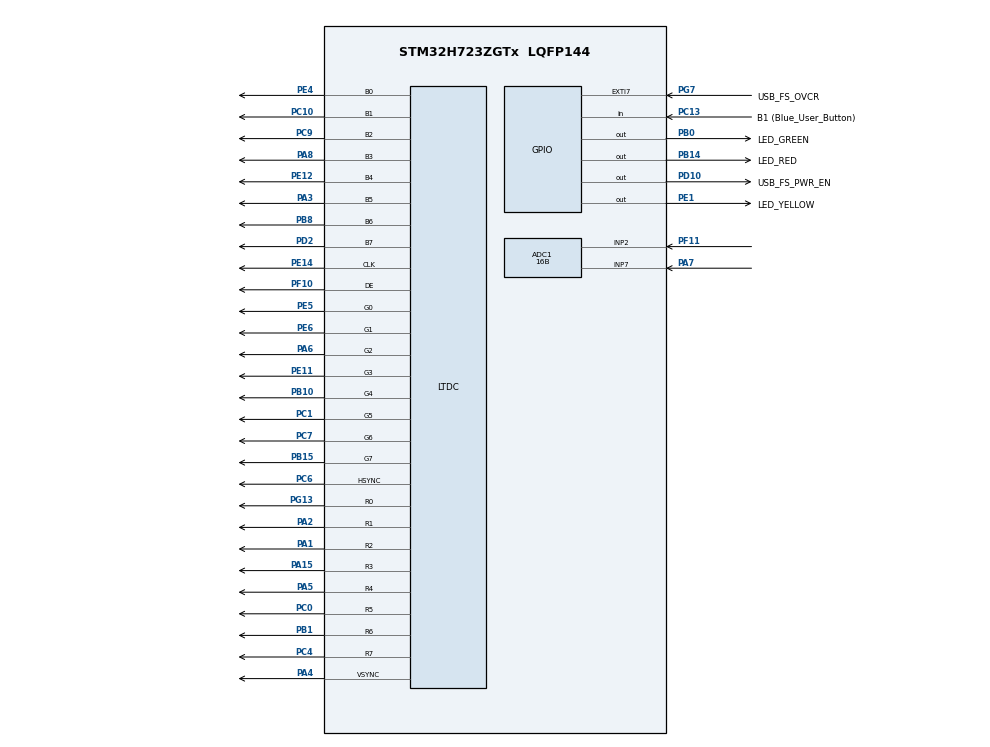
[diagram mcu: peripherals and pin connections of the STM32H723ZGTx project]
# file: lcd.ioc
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ADC1.Channel-1\#ChannelRegularConversion=ADC_CHANNEL_2
ADC1.Channel-2\#ChannelRegularConversion=ADC_CHANNEL_7
ADC1.ContinuousConvMode=DISABLE
ADC1.ConversionDataManagement=ADC_CONVERSIONDATA_DMA_CIRCULAR
ADC1.EOCSelection=ADC_EOC_SEQ_CONV
ADC1.NbrOfConversion=2
ADC1.NbrOfConversionFlag=1
ADC1.OffsetNumber-1\#ChannelRegularConversion=ADC_OFFSET_NONE
ADC1.OffsetNumber-2\#ChannelRegularConversion=ADC_OFFSET_NONE
ADC1.OffsetSignedSaturation-1\#ChannelRegularConversion=DISABLE
ADC1.OffsetSignedSaturation-2\#ChannelRegularConversion=DISABLE
ADC1.Overrun=ADC_OVR_DATA_PRESERVED
ADC1.Rank-1\#ChannelRegularConversion=1
ADC1.Rank-2\#ChannelRegularConversion=2
ADC1.Resolution=ADC_RESOLUTION_16B
ADC1.SamplingTime-1\#ChannelRegularConversion=ADC_SAMPLETIME_1CYCLE_5
ADC1.SamplingTime-2\#ChannelRegularConversion=ADC_SAMPLETIME_1CYCLE_5
ADC1.master=1
Dma.ADC1.0.Direction=DMA_PERIPH_TO_MEMORY
Dma.ADC1.0.EventEnable=DISABLE
Dma.ADC1.0.FIFOMode=DMA_FIFOMODE_DISABLE
Dma.ADC1.0.Instance=DMA1_Stream0
Dma.ADC1.0.MemDataAlignment=DMA_MDATAALIGN_HALFWORD
Dma.ADC1.0.MemInc=DMA_MINC_ENABLE
Dma.ADC1.0.Mode=DMA_CIRCULAR
Dma.ADC1.0.PeriphDataAlignment=DMA_PDATAALIGN_HALFWORD
Dma.ADC1.0.PeriphInc=DMA_PINC_DISABLE
Dma.ADC1.0.Polarity=HAL_DMAMUX_REQ_GEN_RISING
Dma.ADC1.0.Priority=DMA_PRIORITY_LOW
Dma.ADC1.0.RequestNumber=1
Dma.ADC1.0.SignalID=NONE
Dma.ADC1.0.SyncEnable=DISABLE
Dma.ADC1.0.SyncPolarity=HAL_DMAMUX_SYNC_NO_EVENT
Dma.ADC1.0.SyncRequestNumber=1
Dma.ADC1.0.SyncSignalID=NONE
Dma.Request0=ADC1
LTDC.ActiveH=480
LTDC.ActiveW=800
LTDC.Alpha_L0=255
LTDC.DEPolarity=LTDC_DEPOLARITY_AH
LTDC.HBP=8
LTDC.HFP=8
LTDC.HSync=4
LTDC.ImageHeight_L0=800
LTDC.ImageWidth_L0=800
LTDC.Layers=0
LTDC.PixelFormat_L0=LTDC_PIXEL_FORMAT_L8
LTDC.VBP=8
LTDC.VFP=8
LTDC.VSync=8
LTDC.WindowX1_L0=800
LTDC.WindowY1_L0=400
Mcu.Family=STM32H7
Mcu.Name=STM32H723ZGTx
Mcu.Package=LQFP144
NVIC.ADC_IRQn=true\:0\:0\:false\:false\:true\:true\:true\:true
NVIC.DMA1_Stream0_IRQn=true\:0\:0\:false\:false\:true\:false\:true\:true
NVIC.PriorityGroup=NVIC_PRIORITYGROUP_4
PA1.Mode=RGB888
PA1.Signal=LTDC_R2
PA10.GPIO_Label=USB_FS_ID
PA10.Signal=USB_OTG_HS_ID
PA13(JTMS/SWDIO).GPIO_Label=SWDIO
PA13(JTMS/SWDIO).Mode=Serial_Wire
PA13(JTMS/SWDIO).Signal=DEBUG_JTMS-SWDIO
PA14(JTCK/SWCLK).GPIO_Label=SWCLK
PA14(JTCK/SWCLK).Mode=Serial_Wire
PA14(JTCK/SWCLK).Signal=DEBUG_JTCK-SWCLK
PA15(JTDI).Mode=RGB888
PA15(JTDI).Signal=LTDC_R3
PA2.Mode=RGB888
PA2.Signal=LTDC_R1
PA3.Mode=RGB888
PA3.Signal=LTDC_B5
PA4.Mode=RGB888
PA4.Signal=LTDC_VSYNC
PA5.Mode=RGB888
PA5.Signal=LTDC_R4
PA6.Mode=RGB888
PA6.Signal=LTDC_G2
PA7.Signal=ADCx_INP7
PA8.Mode=RGB888
PA8.Signal=LTDC_B3
PA9.GPIO_Label=USB_FS_VBUS
PA9.Signal=USB_OTG_HS_VBUS
PB0.GPIO_Label=LED_GREEN
PB0.Signal=GPIO_Output
PB1.Mode=RGB888
PB1.Signal=LTDC_R6
PB10.Mode=RGB888
PB10.Signal=LTDC_G4
PB14.GPIO_Label=LED_RED
PB14.Signal=GPIO_Output
PB15.Mode=RGB888
PB15.Signal=LTDC_G7
PB3(JTDO/TRACESWO).GPIO_Label=SWO
PB3(JTDO/TRACESWO).Signal=DEBUG_JTDO-SWO
PB8.Mode=RGB888
PB8.Signal=LTDC_B6
PC0.Mode=RGB888
PC0.Signal=LTDC_R5
PC1.Mode=RGB888
PC1.Signal=LTDC_G5
PC10.Mode=RGB888
PC10.Signal=LTDC_B1
PC13.GPIO_Label=B1 (Blue_User_Button)
PC13.Signal=GPIO_Input
PC14-OSC32_IN.Signal=RCC_OSC32_IN
PC15-OSC32_OUT.Signal=RCC_OSC32_OUT
PC4.Mode=RGB888
PC4.Signal=LTDC_R7
PC6.Mode=RGB888
PC6.Signal=LTDC_HSYNC
PC7.Mode=RGB888
PC7.Signal=LTDC_G6
PC9.Mode=RGB888
PC9.Signal=LTDC_B2
PD10.GPIO_Label=USB_FS_PWR_EN
PD10.Signal=GPIO_Output
PD2.Mode=RGB888
PD2.Signal=LTDC_B7
PD8.GPIO_Label=STLK_VCP_RX
PD8.Signal=USART3_TX
PD9.GPIO_Label=STLK_VCP_TX
PD9.Signal=USART3_RX
PE1.GPIO_Label=LED_YELLOW
PE1.Signal=GPIO_Output
PE11.Mode=RGB888
PE11.Signal=LTDC_G3
PE12.Mode=RGB888
PE12.Signal=LTDC_B4
PE14.Mode=RGB888
PE14.Signal=LTDC_CLK
PE4.Mode=RGB888
PE4.Signal=LTDC_B0
PE5.Mode=RGB888
PE5.Signal=LTDC_G0
PE6.Mode=RGB888
PE6.Signal=LTDC_G1
PF10.Mode=RGB888
PF10.Signal=LTDC_DE
PF11.Mode=IN2-Single-Ended
PF11.Signal=ADC1_INP2
PG13.Mode=RGB888
PG13.Signal=LTDC_R0
PG7.GPIO_Label=USB_FS_OVCR
PG7.Signal=GPXTI7
PH0-OSC_IN.GPIO_Label=MCO
PH0-OSC_IN.Signal=RCC_OSC_IN
PH1-OSC_OUT.Signal=RCC_OSC_OUT
ProjectManager.HeapSize=0x200
ProjectManager.StackSize=0x400
ProjectManager.TargetToolchain=Makefile
RCC.ADCFreq_Value=96000000
RCC.APB1Freq_Value=96000000
RCC.APB2Freq_Value=96000000
RCC.APB3Freq_Value=96000000
RCC.APB4Freq_Value=96000000
RCC.CortexFreq_Value=192000000
RCC.D1PPRE=RCC_APB3_DIV2
RCC.D2PPRE1=RCC_APB1_DIV2
RCC.D2PPRE2=RCC_APB2_DIV2
RCC.D3PPRE=RCC_APB4_DIV2
RCC.DIVM1=4
RCC.DIVM2=4
RCC.DIVM3=1
RCC.DIVN1=12
RCC.DIVN2=12
RCC.DIVN3=4
RCC.DIVP1=1
RCC.DIVQ1=4
RCC.DIVR3=12
RCC.HCLKFreq_Value=192000000
RCC.HSE_VALUE=8000000
RCC.PLL2FRACN=0
RCC.PLL3FRACN=5632
RCC.PLLFRACN=0
RCC.PWR_Regulator_Voltage_Scale=PWR_REGULATOR_VOLTAGE_SCALE0
RCC.SYSCLKFreq_VALUE=192000000
RCC.SYSCLKSource=RCC_SYSCLKSOURCE_PLLCLK
RCC.USBCLockSelection=RCC_USBCLKSOURCE_HSI48
RCC.USBFreq_Value=48000000
SH.ADCx_INP7.0=ADC1_INP7,IN7-Single-Ended
board=NUCLEO-H723ZG

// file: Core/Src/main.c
/* USER CODE BEGIN Header */
/**
 ******************************************************************************
 * @file           : main.c
 * @brief          : Main program body
 ******************************************************************************
 * @attention
 *
 * Copyright (c) 2023 STMicroelectronics.
 * All rights reserved.
 *
 * This software is licensed under terms that can be found in the LICENSE file
 * in the root directory of this software component.
 * If no LICENSE file comes with this software, it is provided AS-IS.
 *
 ******************************************************************************
 */
/* USER CODE END Header */
#include "main.h"
#include "adc.h"
#include "dma.h"
#include "gpio.h"
#include "ltdc.h"

/* USER CODE BEGIN Includes */
#include "lcd.h"

/* USER CODE END Includes */

void SystemClock_Config(void);

int main(void) {

    /* MCU
     * Configuration--------------------------------------------------------*/

    /* Reset of all peripherals, Initializes the Flash interface and the
     * Systick. */
    HAL_Init();

    /* Configure the system clock */
    SystemClock_Config();

    /* Initialize all configured peripherals */
    MX_GPIO_Init();
    MX_DMA_Init();
    MX_ADC1_Init();
    MX_LTDC_Init();
    /* USER CODE BEGIN 2 */
    init_display();
    test_display();
    show_calib();
    /* USER CODE END 2 */

    /* Infinite loop */
    /* USER CODE BEGIN WHILE */
    while (1) {
        lv_indev_data_t touch_data;
        read_touch(NULL, &touch_data);
        if (touch_data.state == LV_INDEV_STATE_PR) {
            fb[touch_data.point.y * LCD_RENDER_WIDTH + touch_data.point.x] =
                0xFE;
        }
        /* USER CODE END WHILE */

    }
}

void SystemClock_Config(void) {
    RCC_OscInitTypeDef RCC_OscInitStruct = {0};
    RCC_ClkInitTypeDef RCC_ClkInitStruct = {0};

    /** Supply configuration update enable
     */
    HAL_PWREx_ConfigSupply(PWR_LDO_SUPPLY);

    /** Configure the main internal regulator output voltage
     */
    __HAL_PWR_VOLTAGESCALING_CONFIG(PWR_REGULATOR_VOLTAGE_SCALE0);

    while (!__HAL_PWR_GET_FLAG(PWR_FLAG_VOSRDY)) {
    }

    /** Initializes the RCC Oscillators according to the specified parameters
     * in the RCC_OscInitTypeDef structure.
     */
    RCC_OscInitStruct.OscillatorType = RCC_OSCILLATORTYPE_HSI;
    RCC_OscInitStruct.HSIState = RCC_HSI_DIV1;
    RCC_OscInitStruct.HSICalibrationValue = 64;
    RCC_OscInitStruct.PLL.PLLState = RCC_PLL_ON;
    RCC_OscInitStruct.PLL.PLLSource = RCC_PLLSOURCE_HSI;
    RCC_OscInitStruct.PLL.PLLM = 4;
    RCC_OscInitStruct.PLL.PLLN = 12;
    RCC_OscInitStruct.PLL.PLLP = 1;
    RCC_OscInitStruct.PLL.PLLQ = 4;
    RCC_OscInitStruct.PLL.PLLR = 2;
    RCC_OscInitStruct.PLL.PLLRGE = RCC_PLL1VCIRANGE_3;
    RCC_OscInitStruct.PLL.PLLVCOSEL = RCC_PLL1VCOWIDE;
    RCC_OscInitStruct.PLL.PLLFRACN = 0;
    if (HAL_RCC_OscConfig(&RCC_OscInitStruct) != HAL_OK) {
        Error_Handler();
    }

    /** Initializes the CPU, AHB and APB buses clocks
     */
    RCC_ClkInitStruct.ClockType = RCC_CLOCKTYPE_HCLK | RCC_CLOCKTYPE_SYSCLK |
                                  RCC_CLOCKTYPE_PCLK1 | RCC_CLOCKTYPE_PCLK2 |
                                  RCC_CLOCKTYPE_D3PCLK1 | RCC_CLOCKTYPE_D1PCLK1;
    RCC_ClkInitStruct.SYSCLKSource = RCC_SYSCLKSOURCE_PLLCLK;
    RCC_ClkInitStruct.SYSCLKDivider = RCC_SYSCLK_DIV1;
    RCC_ClkInitStruct.AHBCLKDivider = RCC_HCLK_DIV1;
    RCC_ClkInitStruct.APB3CLKDivider = RCC_APB3_DIV2;
    RCC_ClkInitStruct.APB1CLKDivider = RCC_APB1_DIV2;
    RCC_ClkInitStruct.APB2CLKDivider = RCC_APB2_DIV2;
    RCC_ClkInitStruct.APB4CLKDivider = RCC_APB4_DIV2;

    if (HAL_RCC_ClockConfig(&RCC_ClkInitStruct, FLASH_LATENCY_2) != HAL_OK) {
        Error_Handler();
    }
}

void Error_Handler(void) {
    /* USER CODE BEGIN Error_Handler_Debug */
    /* User can add his own implementation to report the HAL error return state
     */
    __disable_irq();
    while (1) {
    }
    /* USER CODE END Error_Handler_Debug */
}

#ifdef USE_FULL_ASSERT
/**
 * @brief  Reports the name of the source file and the source line number
 *         where the assert_param error has occurred.
 * @param  file: pointer to the source file name
 * @param  line: assert_param error line source number
 * @retval None
 */
void assert_failed(uint8_t *file, uint32_t line) {
    /* USER CODE BEGIN 6 */
    /* User can add his own implementation to report the file name and line
       number, ex: printf("Wrong parameters value: file %s on line %d\r\n",
       file, line) */
    /* USER CODE END 6 */
}
#endif /* USE_FULL_ASSERT */
